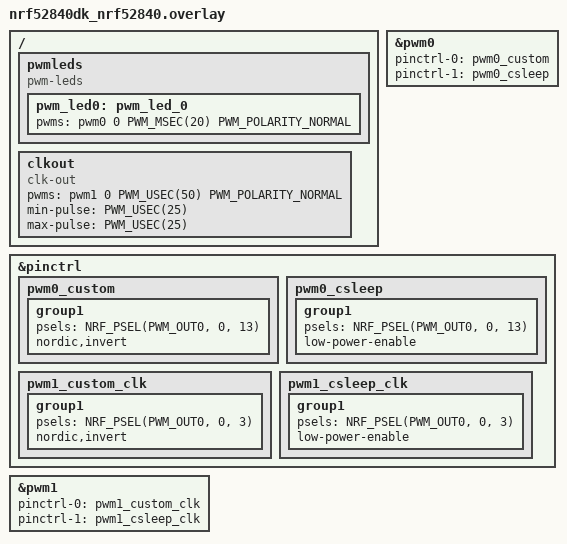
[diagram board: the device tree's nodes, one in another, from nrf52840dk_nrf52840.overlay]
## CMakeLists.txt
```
# SPDX-License-Identifier: Apache-2.0

cmake_minimum_required(VERSION 3.20.0)
find_package(Zephyr REQUIRED HINTS $ENV{ZEPHYR_BASE})
project(blinky)

#target_sources(app PRIVATE src/main.c)

FILE(GLOB app_sources src/*.c)
# NORDIC SDK APP START
target_sources(app PRIVATE ${app_sources})
# NORDIC SDK APP END
```

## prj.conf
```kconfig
#Logging configurations
CONFIG_LOG=y
CONFIG_PWM_LOG_LEVEL_DBG=y
CONFIG_LOG_PRINTK=y
CONFIG_LOG_MODE_IMMEDIATE=y
CONFIG_STDOUT_CONSOLE=y
CONFIG_PRINTK=y

# PWM and LED configurations
CONFIG_PWM=y
CONFIG_LED=y
CONFIG_LED_PWM=y

# DK Buttons and LEDs library
CONFIG_DK_LIBRARY=y
```

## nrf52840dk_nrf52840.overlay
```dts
// To get started, press Ctrl+Space to bring up the completion menu and view the available nodes.

// You can also use the buttons in the sidebar to perform actions on nodes.
// Actions currently available include:

// * Enabling / disabling the node
// * Adding the bus to a bus
// * Removing the node
// * Connecting ADC channels

// For more help, browse the DeviceTree documentation at https://docs.zephyrproject.org/latest/guides/dts/index.html
// You can also visit the nRF DeviceTree extension documentation at https://docs.nordicsemi.com/bundle/nrf-connect-vscode/page/guides/ncs_configure_app.html#devicetree-support-in-the-extension
/{
    pwmleds {
        compatible = "pwm-leds";
        pwm_led0: pwm_led_0 {
        pwms = <&pwm0 0 PWM_MSEC(20) PWM_POLARITY_NORMAL>;
    };
 };
};

/ {
    clkout: clkout {
        compatible = "clk-out";
        pwms = <&pwm1 0 PWM_USEC(50) PWM_POLARITY_NORMAL>;
        min-pulse = <PWM_USEC(25)>;
        max-pulse = <PWM_USEC(25)>;
    };
};

&pwm0 {
	status = "okay";
	pinctrl-0 = <&pwm0_custom>;
	pinctrl-1 = <&pwm0_csleep>;
	pinctrl-names = "default", "sleep";
};

&pinctrl {
    pwm0_custom: pwm0_custom {
        group1 {
            psels = <NRF_PSEL(PWM_OUT0, 0, 13)>;
            nordic,invert;
        };
    };

    pwm0_csleep: pwm0_csleep {
        group1 {
            psels = <NRF_PSEL(PWM_OUT0, 0, 13)>;
            low-power-enable;
        };
    };
};


&pwm1 {
    status = "okay";
    pinctrl-0 = <&pwm1_custom_clk>;
    pinctrl-1 = <&pwm1_csleep_clk>;
    pinctrl-names = "default", "sleep";
};

&pinctrl {
    pwm1_custom_clk: pwm1_custom_clk {
        group1 {
            psels = <NRF_PSEL(PWM_OUT0, 0, 3)>;
            nordic,invert;
        };
    };
    pwm1_csleep_clk: pwm1_csleep_clk {
        group1 {
            psels = <NRF_PSEL(PWM_OUT0, 0, 3)>;
            low-power-enable;
        };
    };
};
```

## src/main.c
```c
/*
 * Copyright (c) 2024 Nordic Semiconductor ASA
 *
 * SPDX-License-Identifier: LicenseRef-Nordic-5-Clause
 */
 
#include <zephyr/kernel.h>
#include <zephyr/logging/log.h>
#include <zephyr/device.h>
#include <zephyr/drivers/pwm.h>
#include <dk_buttons_and_leds.h>

LOG_MODULE_REGISTER(Lesson4_Exercise2, LOG_LEVEL_INF);

#include "pwm_clk.h"

void button_handler(uint32_t button_state, uint32_t has_changed)
{
    int err = 0;
	if (has_changed & button_state)
	{
		switch (has_changed)
		{
            /* STEP 2.4 - Change motor angle when a button is pressed */
            /* STEP 5.6 - Update the button handler with the new duty cycle */
            case DK_BTN1_MSK:
                LOG_INF("Button 1 pressed");
                //err = set_motor_angle(0);
				err = pwm_clk_stop();
                break;
            case DK_BTN2_MSK:
                LOG_INF("Button 2 pressed");
                //err = set_motor_angle(PWM_CLK_PULSE_WIDTH);
				err = pwm_clk_start();
                break;       
			default:
				break;
		}
        if (err) {
            LOG_ERR("Error: couldn't set duty cycle, err %d", err);
        }
	}
}

int main(void)
{

    int err = 0;
    	
    if (dk_buttons_init(button_handler)) {
        LOG_ERR("Failed to initialize the buttons library");
    }
	
    err = pwm_clk_setup();
    if (!err) {
        LOG_ERR("Error: PWM_CLK device %s is not ready");
    } else {
        pwm_clk_start();
    }

    return 0;
}
```

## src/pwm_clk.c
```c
#include "pwm_clk.h"


static const struct pwm_dt_spec pwm_clk_out = PWM_DT_SPEC_GET(CLK_OUT);

int pwm_clk_setup()
{
     int err = 0;

    //LOG_INF("Setting CLK");
    if (!pwm_is_ready_dt(&pwm_clk_out)) {
        //LOG_ERR("Error: PWM device %s is not ready", pwm_clk_out.dev->name);
        return 0;
	}
}

int pwm_clk_start()
{
    int err;
    
    err = pwm_set_dt(&pwm_clk_out, PWM_CLK_PERIOD, PWM_CLK_PULSE_WIDTH);
    if (err) {
        //LOG_ERR("pwm_set_dt_returned %d", err);
    }
    return err;
}

int pwm_clk_stop()
{
    int err;
    
    err = pwm_set_dt(&pwm_clk_out, PWM_CLK_PERIOD, 0);
    if (err) {
        //LOG_ERR("pwm_set_dt_returned %d", err);
    }
    return err;
}
```
